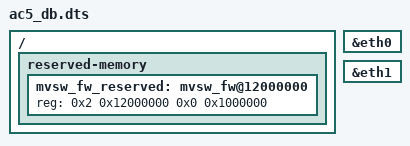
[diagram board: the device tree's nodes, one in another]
// SPDX-License-Identifier: (GPL-2.0+ OR MIT)
/*
 * Device Tree For AC5X.
 *
 * Copyright (C) 2016 Marvell
 *
 */
// SPDX-License-Identifier: (GPL-2.0+ OR MIT)
/*
 * Device Tree file for Marvell Armada 7040 development board
 * This board file supports the B configuration of the board
 */

#include "ac5.dtsi"
/ {
	reserved-memory {
		#address-cells = <2>;
		#size-cells = <2>;
		ranges;

		mvsw_fw_reserved: mvsw_fw@12000000 {
			reg = <0x2 0x12000000 0x0 0x1000000>;
		};
	};

};

&eth0 {
	status = "okay";
};

&eth1 {
	status = "okay";
};

